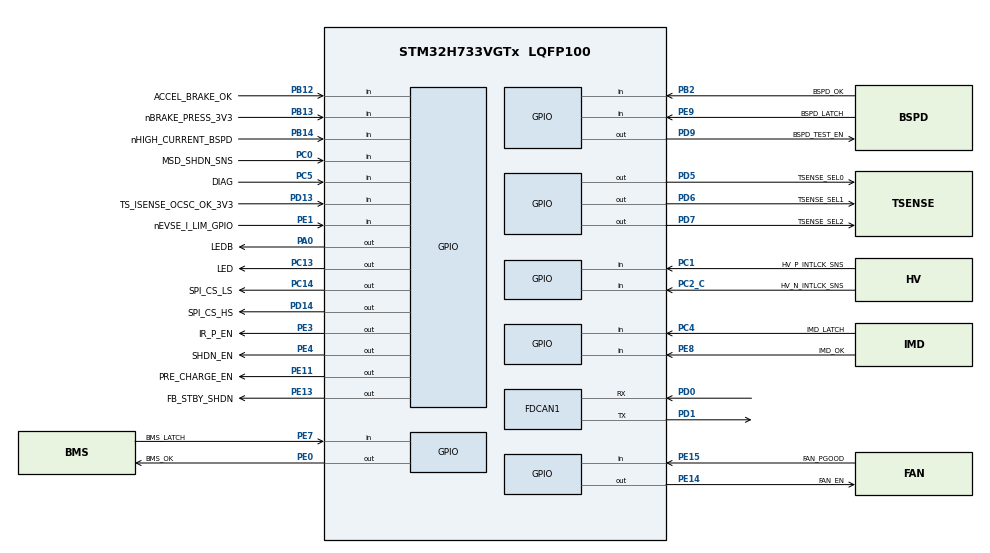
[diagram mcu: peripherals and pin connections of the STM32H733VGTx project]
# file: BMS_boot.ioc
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CORTEX_M7.default_mode_Activation=0
FDCAN1.AutoRetransmission=ENABLE
FDCAN1.CalculateBaudRateNominal=1000000
FDCAN1.CalculateTimeBitNominal=1000
FDCAN1.CalculateTimeQuantumNominal=62.5
FDCAN1.DataSyncJumpWidth=6
FDCAN1.DataTimeSeg1=17
FDCAN1.DataTimeSeg2=6
FDCAN1.ExtFiltersNbr=1
FDCAN1.FrameFormat=FDCAN_FRAME_FD_NO_BRS
FDCAN1.NominalPrescaler=6
FDCAN1.NominalSyncJumpWidth=2
FDCAN1.NominalTimeSeg1=13
FDCAN1.NominalTimeSeg2=2
FDCAN1.ProtocolException=DISABLE
FDCAN1.RxBufferSize=FDCAN_DATA_BYTES_64
FDCAN1.RxFifo0ElmtSize=FDCAN_DATA_BYTES_64
FDCAN1.RxFifo0ElmtsNbr=32
FDCAN1.RxFifo1ElmtSize=FDCAN_DATA_BYTES_64
FDCAN1.RxFifo1ElmtsNbr=0
FDCAN1.StdFiltersNbr=1
FDCAN1.TxElmtSize=FDCAN_DATA_BYTES_64
FDCAN1.TxFifoQueueElmtsNbr=32
FREERTOS.Tasks01=interfaceTask,48,512,runInterfaceTask,Default,NULL,Static,interfaceTaskBuffer,interfaceTaskControlBlock;canTxTask,40,512,runCanTxTask,Default,NULL,Static,canTxTaskBuffer,canTxTaskControlBlock;tickTask,16,512,runTickTask,Default,NULL,Static,tickTaskBuffer,tickTaskControlBlock
FREERTOS.configENABLE_FPU=1
FREERTOS.configUSE_NEWLIB_REENTRANT=1
Mcu.Family=STM32H7
Mcu.Name=STM32H733VGTx
Mcu.Package=LQFP100
Mcu.UserConstants=TIM3_PRESCALER,10;ADC_FREQUENCY,1000;TASKCANTX_STACK_SIZE,512;TIM1_AUTO_RELOAD_REG,0xFFFF;TIMx_FREQUENCY,550000000;IWDG_RESET_FREQUENCY,5;TASK1KHZ_STACK_SIZE,512;TIM1_FREQUENCY,275000000;TIM3_FREQUENCY,275000000;TASK100HZ_STACK_SIZE,512;TASK1HZ_STACK_SIZE,512;IWDG_WINDOW_DISABLE_VALUE,4095;IWDG_PRESCALER,4;TASKCANRX_STACK_SIZE,512;TIM1_PWM_MIN_FREQUENCY,1;LSI_FREQUENCY,32000;TIM1_PRESCALER,(TIM1_FREQUENCY / TIM1_AUTO_RELOAD_REG / TIM1_PWM_MIN_FREQUENCY);TIM5_FREQUENCY,275000000;TIM5_AUTO_RELOAD_REG,0xFFFF;TIM5_PWM_MIN_FREQUENCY,1;TIM5_PRESCALER,(TIM5_FREQUENCY / TIM5_AUTO_RELOAD_REG / TIM5_PWM_MIN_FREQUENCY)
NVIC.FDCAN1_IT0_IRQn=true\:5\:0\:false\:false\:true\:true\:true\:true\:true
NVIC.FDCAN1_IT1_IRQn=true\:5\:0\:false\:false\:true\:true\:true\:true\:true
NVIC.PriorityGroup=NVIC_PRIORITYGROUP_4
NVIC.TIM2_IRQn=true\:15\:0\:false\:false\:true\:false\:false\:true\:true
NVIC.TimeBase=TIM2_IRQn
NVIC.TimeBaseIP=TIM2
PA0.GPIO_Label=LEDB
PA0.PinState=GPIO_PIN_SET
PA0.Signal=GPIO_Output
PA13(JTMS/SWDIO).GPIO_Label=SWDIO
PA13(JTMS/SWDIO).Mode=Trace_Asynchronous_SW
PA13(JTMS/SWDIO).Signal=DEBUG_JTMS-SWDIO
PA14(JTCK/SWCLK).GPIO_Label=SWCLK
PA14(JTCK/SWCLK).Mode=Trace_Asynchronous_SW
PA14(JTCK/SWCLK).Signal=DEBUG_JTCK-SWCLK
PB12.GPIO_Label=ACCEL_BRAKE_OK
PB12.Signal=GPIO_Input
PB13.GPIO_Label=nBRAKE_PRESS_3V3
PB13.Signal=GPIO_Input
PB14.GPIO_Label=nHIGH_CURRENT_BSPD
PB14.Signal=GPIO_Input
PB2.GPIO_Label=BSPD_OK
PB2.Signal=GPIO_Input
PB3(JTDO/TRACESWO).GPIO_Label=SWO
PB3(JTDO/TRACESWO).Mode=Trace_Asynchronous_SW
PB3(JTDO/TRACESWO).Signal=DEBUG_JTDO-SWO
PB5.Signal=FDCAN2_RX
PB6.Signal=FDCAN2_TX
PC0.GPIO_Label=MSD_SHDN_SNS
PC0.Signal=GPIO_Input
PC1.GPIO_Label=HV_P_INTLCK_SNS
PC1.Signal=GPIO_Input
PC13.GPIO_Label=LED
PC13.Signal=GPIO_Output
PC14-OSC32_IN.GPIO_Label=SPI_CS_LS
PC14-OSC32_IN.GPIO_PuPd=GPIO_NOPULL
PC14-OSC32_IN.GPIO_Speed=GPIO_SPEED_FREQ_LOW
PC14-OSC32_IN.PinState=GPIO_PIN_SET
PC14-OSC32_IN.Signal=GPIO_Output
PC2_C.GPIO_Label=HV_N_INTLCK_SNS
PC2_C.Signal=GPIO_Input
PC4.GPIO_Label=IMD_LATCH
PC4.Signal=GPIO_Input
PC5.GPIO_Label=DIAG
PC5.Signal=GPIO_Input
PD0.Mode=FDCAN_Activate
PD0.Signal=FDCAN1_RX
PD1.Mode=FDCAN_Activate
PD1.Signal=FDCAN1_TX
PD13.GPIO_Label=TS_ISENSE_OCSC_OK_3V3
PD13.Signal=GPIO_Input
PD14.GPIO_Label=SPI_CS_HS
PD14.GPIO_PuPd=GPIO_NOPULL
PD14.GPIO_Speed=GPIO_SPEED_FREQ_LOW
PD14.PinState=GPIO_PIN_SET
PD14.Signal=GPIO_Output
PD5.GPIO_Label=TSENSE_SEL0
PD5.Signal=GPIO_Output
PD6.GPIO_Label=TSENSE_SEL1
PD6.Signal=GPIO_Output
PD7.GPIO_Label=TSENSE_SEL2
PD7.Signal=GPIO_Output
PD9.GPIO_Label=BSPD_TEST_EN
PD9.Signal=GPIO_Output
PE0.GPIO_Label=BMS_OK
PE0.Signal=GPIO_Output
PE1.GPIO_Label=nEVSE_I_LIM_GPIO
PE1.Signal=GPIO_Input
PE11.GPIO_Label=PRE_CHARGE_EN
PE11.GPIO_PuPd=GPIO_PULLDOWN
PE11.Signal=GPIO_Output
PE13.GPIO_Label=FB_STBY_SHDN
PE13.Signal=GPIO_Output
PE14.GPIO_Label=FAN_EN
PE14.GPIO_ModeDefaultOutputPP=GPIO_MODE_OUTPUT_OD
PE14.GPIO_PuPd=GPIO_NOPULL
PE14.Signal=GPIO_Output
PE15.GPIO_Label=FAN_PGOOD
PE15.Signal=GPIO_Input
PE3.GPIO_Label=IR_P_EN
PE3.Signal=GPIO_Output
PE4.GPIO_Label=SHDN_EN
PE4.Signal=GPIO_Output
PE7.GPIO_Label=BMS_LATCH
PE7.Signal=GPIO_Input
PE8.GPIO_Label=IMD_OK
PE8.Signal=GPIO_Input
PE9.GPIO_Label=BSPD_LATCH
PE9.Signal=GPIO_Input
PH0-OSC_IN.Mode=HSE-External-Oscillator
PH0-OSC_IN.Signal=RCC_OSC_IN
PH1-OSC_OUT.Mode=HSE-External-Oscillator
PH1-OSC_OUT.Signal=RCC_OSC_OUT
ProjectManager.HeapSize=0x200
ProjectManager.StackSize=0x400
ProjectManager.TargetToolchain=STM32CubeIDE
RCC.ADCFreq_Value=96000000
RCC.APB1Freq_Value=128000000
RCC.APB2Freq_Value=128000000
RCC.APB3Freq_Value=128000000
RCC.APB4Freq_Value=128000000
RCC.CortexFreq_Value=512000000
RCC.D1PPRE=RCC_APB3_DIV2
RCC.D2PPRE1=RCC_APB1_DIV2
RCC.D2PPRE2=RCC_APB2_DIV2
RCC.D3PPRE=RCC_APB4_DIV2
RCC.DIVM1=1
RCC.DIVM2=1
RCC.DIVM3=1
RCC.DIVN1=64
RCC.DIVN2=24
RCC.DIVN3=24
RCC.DIVP1=1
RCC.DIVQ1=4
RCC.DIVQ3=4
RCC.FDCANCLockSelection=RCC_FDCANCLKSOURCE_PLL2
RCC.HCLKFreq_Value=256000000
RCC.HPRE=RCC_HCLK_DIV2
RCC.HSE_VALUE=8000000
RCC.HSIDiv=RCC_PLLSAIDIVR_8
RCC.PLL2FRACN=0
RCC.PLL3FRACN=0
RCC.PLLFRACN=0
RCC.PLLSourceVirtual=RCC_PLLSOURCE_HSE
RCC.SYSCLKFreq_VALUE=512000000
RCC.SYSCLKSource=RCC_SYSCLKSOURCE_PLLCLK
RCC.Spi45ClockSelection=RCC_SPI45CLKSOURCE_PLL2
RCC.USBCLockSelection=RCC_USBCLKSOURCE_PLL3
RCC.USBFreq_Value=48000000
VP_FREERTOS_VS_CMSIS_V2.Mode=CMSIS_V2
VP_MEMORYMAP_VS_MEMORYMAP.Mode=CurAppReg
VP_SYS_VS_tim2.Mode=TIM2
board=custom

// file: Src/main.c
/* USER CODE BEGIN Header */
/**
 ******************************************************************************
 * @file           : main.c
 * @brief          : Main program body
 ******************************************************************************
 * @attention
 *
 * Copyright (c) 2024 STMicroelectronics.
 * All rights reserved.
 *
 * This software is licensed under terms that can be found in the LICENSE file
 * in the root directory of this software component.
 * If no LICENSE file comes with this software, it is provided AS-IS.
 *
 ******************************************************************************
 */
/* USER CODE END Header */
#include "main.h"
#include "cmsis_os.h"

/* USER CODE BEGIN Includes */
#include "hw/fdcan.h"
#include "hw/error.h"
#include "io/canQueue.h"

#include "bootloader.h"
/* USER CODE END Includes */

typedef StaticTask_t osStaticThreadDef_t;

FDCAN_HandleTypeDef hfdcan1;

/* Definitions for interfaceTask */
osThreadId_t         interfaceTaskHandle;
uint32_t             interfaceTaskBuffer[512];
osStaticThreadDef_t  interfaceTaskControlBlock;
const osThreadAttr_t interfaceTask_attributes = {
    .name       = "interfaceTask",
    .cb_mem     = &interfaceTaskControlBlock,
    .cb_size    = sizeof(interfaceTaskControlBlock),
    .stack_mem  = &interfaceTaskBuffer[0],
    .stack_size = sizeof(interfaceTaskBuffer),
    .priority   = (osPriority_t)osPriorityRealtime,
};
/* Definitions for canTxTask */
osThreadId_t         canTxTaskHandle;
uint32_t             canTxTaskBuffer[512];
osStaticThreadDef_t  canTxTaskControlBlock;
const osThreadAttr_t canTxTask_attributes = {
    .name       = "canTxTask",
    .cb_mem     = &canTxTaskControlBlock,
    .cb_size    = sizeof(canTxTaskControlBlock),
    .stack_mem  = &canTxTaskBuffer[0],
    .stack_size = sizeof(canTxTaskBuffer),
    .priority   = (osPriority_t)osPriorityHigh,
};
/* Definitions for tickTask */
osThreadId_t         tickTaskHandle;
uint32_t             tickTaskBuffer[512];
osStaticThreadDef_t  tickTaskControlBlock;
const osThreadAttr_t tickTask_attributes = {
    .name       = "tickTask",
    .cb_mem     = &tickTaskControlBlock,
    .cb_size    = sizeof(tickTaskControlBlock),
    .stack_mem  = &tickTaskBuffer[0],
    .stack_size = sizeof(tickTaskBuffer),
    .priority   = (osPriority_t)osPriorityBelowNormal,
};
/* USER CODE BEGIN PV */
CanHandle can = { .bus_num = 0, .hcan = &hfdcan1, .receive_callback = io_canQueue_pushRx, .ready = false };
/* USER CODE END PV */

void        SystemClock_Config(void);
static void MX_GPIO_Init(void);
static void MX_FDCAN1_Init(void);
void        runInterfaceTask(void *argument);
void        runCanTxTask(void *argument);
void        runTickTask(void *argument);

int main(void)
{
    /* USER CODE BEGIN 1 */
    bootloader_preInit();
    /* USER CODE END 1 */

    /* MCU Configuration--------------------------------------------------------*/

    /* Reset of all peripherals, Initializes the Flash interface and the Systick. */
    HAL_Init();

    /* Configure the system clock */
    SystemClock_Config();

    /* Initialize all configured peripherals */
    MX_GPIO_Init();
    MX_FDCAN1_Init();
    /* USER CODE BEGIN 2 */
    bootloader_init();
    /* USER CODE END 2 */

    /* Init scheduler */
    osKernelInitialize();

    /* Create the thread(s) */
    /* creation of interfaceTask */
    interfaceTaskHandle = osThreadNew(runInterfaceTask, NULL, &interfaceTask_attributes);

    /* creation of canTxTask */
    canTxTaskHandle = osThreadNew(runCanTxTask, NULL, &canTxTask_attributes);

    /* creation of tickTask */
    tickTaskHandle = osThreadNew(runTickTask, NULL, &tickTask_attributes);

    /* Start scheduler */
    osKernelStart();

    /* We should never get here as control is now taken by the scheduler */

    /* Infinite loop */
    while (1)
    {

    }
}

void SystemClock_Config(void)
{
    RCC_OscInitTypeDef RCC_OscInitStruct = { 0 };
    RCC_ClkInitTypeDef RCC_ClkInitStruct = { 0 };

    /** Supply configuration update enable
     */
    HAL_PWREx_ConfigSupply(PWR_LDO_SUPPLY);

    /** Configure the main internal regulator output voltage
     */
    __HAL_PWR_VOLTAGESCALING_CONFIG(PWR_REGULATOR_VOLTAGE_SCALE0);

    while (!__HAL_PWR_GET_FLAG(PWR_FLAG_VOSRDY))
    {
    }

    /** Initializes the RCC Oscillators according to the specified parameters
     * in the RCC_OscInitTypeDef structure.
     */
    RCC_OscInitStruct.OscillatorType = RCC_OSCILLATORTYPE_HSE;
    RCC_OscInitStruct.HSEState       = RCC_HSE_ON;
    RCC_OscInitStruct.PLL.PLLState   = RCC_PLL_ON;
    RCC_OscInitStruct.PLL.PLLSource  = RCC_PLLSOURCE_HSE;
    RCC_OscInitStruct.PLL.PLLM       = 1;
    RCC_OscInitStruct.PLL.PLLN       = 64;
    RCC_OscInitStruct.PLL.PLLP       = 1;
    RCC_OscInitStruct.PLL.PLLQ       = 4;
    RCC_OscInitStruct.PLL.PLLR       = 2;
    RCC_OscInitStruct.PLL.PLLRGE     = RCC_PLL1VCIRANGE_3;
    RCC_OscInitStruct.PLL.PLLVCOSEL  = RCC_PLL1VCOWIDE;
    RCC_OscInitStruct.PLL.PLLFRACN   = 0;
    if (HAL_RCC_OscConfig(&RCC_OscInitStruct) != HAL_OK)
    {
        Error_Handler();
    }

    /** Initializes the CPU, AHB and APB buses clocks
     */
    RCC_ClkInitStruct.ClockType = RCC_CLOCKTYPE_HCLK | RCC_CLOCKTYPE_SYSCLK | RCC_CLOCKTYPE_PCLK1 |
                                  RCC_CLOCKTYPE_PCLK2 | RCC_CLOCKTYPE_D3PCLK1 | RCC_CLOCKTYPE_D1PCLK1;
    RCC_ClkInitStruct.SYSCLKSource   = RCC_SYSCLKSOURCE_PLLCLK;
    RCC_ClkInitStruct.SYSCLKDivider  = RCC_SYSCLK_DIV1;
    RCC_ClkInitStruct.AHBCLKDivider  = RCC_HCLK_DIV2;
    RCC_ClkInitStruct.APB3CLKDivider = RCC_APB3_DIV2;
    RCC_ClkInitStruct.APB1CLKDivider = RCC_APB1_DIV2;
    RCC_ClkInitStruct.APB2CLKDivider = RCC_APB2_DIV2;
    RCC_ClkInitStruct.APB4CLKDivider = RCC_APB4_DIV2;

    if (HAL_RCC_ClockConfig(&RCC_ClkInitStruct, FLASH_LATENCY_3) != HAL_OK)
    {
        Error_Handler();
    }
}

static void MX_FDCAN1_Init(void)
{

    hfdcan1.Instance                  = FDCAN1;
    hfdcan1.Init.FrameFormat          = FDCAN_FRAME_FD_NO_BRS;
    hfdcan1.Init.Mode                 = FDCAN_MODE_NORMAL;
    hfdcan1.Init.AutoRetransmission   = ENABLE;
    hfdcan1.Init.TransmitPause        = DISABLE;
    hfdcan1.Init.ProtocolException    = DISABLE;
    hfdcan1.Init.NominalPrescaler     = 6;
    hfdcan1.Init.NominalSyncJumpWidth = 2;
    hfdcan1.Init.NominalTimeSeg1      = 13;
    hfdcan1.Init.NominalTimeSeg2      = 2;
    hfdcan1.Init.DataPrescaler        = 1;
    hfdcan1.Init.DataSyncJumpWidth    = 6;
    hfdcan1.Init.DataTimeSeg1         = 17;
    hfdcan1.Init.DataTimeSeg2         = 6;
    hfdcan1.Init.MessageRAMOffset     = 0;
    hfdcan1.Init.StdFiltersNbr        = 1;
    hfdcan1.Init.ExtFiltersNbr        = 1;
    hfdcan1.Init.RxFifo0ElmtsNbr      = 32;
    hfdcan1.Init.RxFifo0ElmtSize      = FDCAN_DATA_BYTES_64;
    hfdcan1.Init.RxFifo1ElmtsNbr      = 0;
    hfdcan1.Init.RxFifo1ElmtSize      = FDCAN_DATA_BYTES_64;
    hfdcan1.Init.RxBuffersNbr         = 0;
    hfdcan1.Init.RxBufferSize         = FDCAN_DATA_BYTES_64;
    hfdcan1.Init.TxEventsNbr          = 0;
    hfdcan1.Init.TxBuffersNbr         = 0;
    hfdcan1.Init.TxFifoQueueElmtsNbr  = 32;
    hfdcan1.Init.TxFifoQueueMode      = FDCAN_TX_FIFO_OPERATION;
    hfdcan1.Init.TxElmtSize           = FDCAN_DATA_BYTES_64;
    if (HAL_FDCAN_Init(&hfdcan1) != HAL_OK)
    {
        Error_Handler();
    }
}

static void MX_GPIO_Init(void)
{
    GPIO_InitTypeDef GPIO_InitStruct = { 0 };

    /* GPIO Ports Clock Enable */
    __HAL_RCC_GPIOE_CLK_ENABLE();
    __HAL_RCC_GPIOC_CLK_ENABLE();
    __HAL_RCC_GPIOH_CLK_ENABLE();
    __HAL_RCC_GPIOA_CLK_ENABLE();
    __HAL_RCC_GPIOB_CLK_ENABLE();
    __HAL_RCC_GPIOD_CLK_ENABLE();

    /*Configure GPIO pin Output Level */
    HAL_GPIO_WritePin(
        GPIOE, IR_P_EN_Pin | SHDN_EN_Pin | PRE_CHARGE_EN_Pin | FB_STBY_SHDN_Pin | FAN_EN_Pin | BMS_OK_Pin,
        GPIO_PIN_RESET);

    /*Configure GPIO pin Output Level */
    HAL_GPIO_WritePin(LED_GPIO_Port, LED_Pin, GPIO_PIN_RESET);

    /*Configure GPIO pin Output Level */
    HAL_GPIO_WritePin(SPI_CS_LS_GPIO_Port, SPI_CS_LS_Pin, GPIO_PIN_SET);

    /*Configure GPIO pin Output Level */
    HAL_GPIO_WritePin(LEDB_GPIO_Port, LEDB_Pin, GPIO_PIN_SET);

    /*Configure GPIO pin Output Level */
    HAL_GPIO_WritePin(GPIOD, BSPD_TEST_EN_Pin | TSENSE_SEL0_Pin | TSENSE_SEL1_Pin | TSENSE_SEL2_Pin, GPIO_PIN_RESET);

    /*Configure GPIO pin Output Level */
    HAL_GPIO_WritePin(SPI_CS_HS_GPIO_Port, SPI_CS_HS_Pin, GPIO_PIN_SET);

    /*Configure GPIO pins : IR_P_EN_Pin SHDN_EN_Pin FB_STBY_SHDN_Pin BMS_OK_Pin */
    GPIO_InitStruct.Pin   = IR_P_EN_Pin | SHDN_EN_Pin | FB_STBY_SHDN_Pin | BMS_OK_Pin;
    GPIO_InitStruct.Mode  = GPIO_MODE_OUTPUT_PP;
    GPIO_InitStruct.Pull  = GPIO_NOPULL;
    GPIO_InitStruct.Speed = GPIO_SPEED_FREQ_LOW;
    HAL_GPIO_Init(GPIOE, &GPIO_InitStruct);

    /*Configure GPIO pins : LED_Pin SPI_CS_LS_Pin */
    GPIO_InitStruct.Pin   = LED_Pin | SPI_CS_LS_Pin;
    GPIO_InitStruct.Mode  = GPIO_MODE_OUTPUT_PP;
    GPIO_InitStruct.Pull  = GPIO_NOPULL;
    GPIO_InitStruct.Speed = GPIO_SPEED_FREQ_LOW;
    HAL_GPIO_Init(GPIOC, &GPIO_InitStruct);

    /*Configure GPIO pins : MSD_SHDN_SNS_Pin HV_P_INTLCK_SNS_Pin HV_N_INTLCK_SNS_Pin IMD_LATCH_Pin
                             DIAG_Pin */
    GPIO_InitStruct.Pin  = MSD_SHDN_SNS_Pin | HV_P_INTLCK_SNS_Pin | HV_N_INTLCK_SNS_Pin | IMD_LATCH_Pin | DIAG_Pin;
    GPIO_InitStruct.Mode = GPIO_MODE_INPUT;
    GPIO_InitStruct.Pull = GPIO_NOPULL;
    HAL_GPIO_Init(GPIOC, &GPIO_InitStruct);

    /*Configure GPIO pin : LEDB_Pin */
    GPIO_InitStruct.Pin   = LEDB_Pin;
    GPIO_InitStruct.Mode  = GPIO_MODE_OUTPUT_PP;
    GPIO_InitStruct.Pull  = GPIO_NOPULL;
    GPIO_InitStruct.Speed = GPIO_SPEED_FREQ_LOW;
    HAL_GPIO_Init(LEDB_GPIO_Port, &GPIO_InitStruct);

    /*Configure GPIO pins : BSPD_OK_Pin ACCEL_BRAKE_OK_Pin nBRAKE_PRESS_3V3_Pin nHIGH_CURRENT_BSPD_Pin */
    GPIO_InitStruct.Pin  = BSPD_OK_Pin | ACCEL_BRAKE_OK_Pin | nBRAKE_PRESS_3V3_Pin | nHIGH_CURRENT_BSPD_Pin;
    GPIO_InitStruct.Mode = GPIO_MODE_INPUT;
    GPIO_InitStruct.Pull = GPIO_NOPULL;
    HAL_GPIO_Init(GPIOB, &GPIO_InitStruct);

    /*Configure GPIO pins : BMS_LATCH_Pin IMD_OK_Pin BSPD_LATCH_Pin FAN_PGOOD_Pin
                             nEVSE_I_LIM_GPIO_Pin */
    GPIO_InitStruct.Pin  = BMS_LATCH_Pin | IMD_OK_Pin | BSPD_LATCH_Pin | FAN_PGOOD_Pin | nEVSE_I_LIM_GPIO_Pin;
    GPIO_InitStruct.Mode = GPIO_MODE_INPUT;
    GPIO_InitStruct.Pull = GPIO_NOPULL;
    HAL_GPIO_Init(GPIOE, &GPIO_InitStruct);

    /*Configure GPIO pin : PRE_CHARGE_EN_Pin */
    GPIO_InitStruct.Pin   = PRE_CHARGE_EN_Pin;
    GPIO_InitStruct.Mode  = GPIO_MODE_OUTPUT_PP;
    GPIO_InitStruct.Pull  = GPIO_PULLDOWN;
    GPIO_InitStruct.Speed = GPIO_SPEED_FREQ_LOW;
    HAL_GPIO_Init(PRE_CHARGE_EN_GPIO_Port, &GPIO_InitStruct);

    /*Configure GPIO pin : FAN_EN_Pin */
    GPIO_InitStruct.Pin   = FAN_EN_Pin;
    GPIO_InitStruct.Mode  = GPIO_MODE_OUTPUT_OD;
    GPIO_InitStruct.Pull  = GPIO_NOPULL;
    GPIO_InitStruct.Speed = GPIO_SPEED_FREQ_LOW;
    HAL_GPIO_Init(FAN_EN_GPIO_Port, &GPIO_InitStruct);

    /*Configure GPIO pins : BSPD_TEST_EN_Pin SPI_CS_HS_Pin TSENSE_SEL0_Pin TSENSE_SEL1_Pin
                             TSENSE_SEL2_Pin */
    GPIO_InitStruct.Pin   = BSPD_TEST_EN_Pin | SPI_CS_HS_Pin | TSENSE_SEL0_Pin | TSENSE_SEL1_Pin | TSENSE_SEL2_Pin;
    GPIO_InitStruct.Mode  = GPIO_MODE_OUTPUT_PP;
    GPIO_InitStruct.Pull  = GPIO_NOPULL;
    GPIO_InitStruct.Speed = GPIO_SPEED_FREQ_LOW;
    HAL_GPIO_Init(GPIOD, &GPIO_InitStruct);

    /*Configure GPIO pin : TS_ISENSE_OCSC_OK_3V3_Pin */
    GPIO_InitStruct.Pin  = TS_ISENSE_OCSC_OK_3V3_Pin;
    GPIO_InitStruct.Mode = GPIO_MODE_INPUT;
    GPIO_InitStruct.Pull = GPIO_NOPULL;
    HAL_GPIO_Init(TS_ISENSE_OCSC_OK_3V3_GPIO_Port, &GPIO_InitStruct);

    /*Configure GPIO pins : PB5 PB6 */
    GPIO_InitStruct.Pin       = GPIO_PIN_5 | GPIO_PIN_6;
    GPIO_InitStruct.Mode      = GPIO_MODE_AF_PP;
    GPIO_InitStruct.Pull      = GPIO_NOPULL;
    GPIO_InitStruct.Speed     = GPIO_SPEED_FREQ_LOW;
    GPIO_InitStruct.Alternate = GPIO_AF9_FDCAN2;
    HAL_GPIO_Init(GPIOB, &GPIO_InitStruct);

}

void runInterfaceTask(void *argument)
{
    /* USER CODE BEGIN 5 */
    /* Infinite loop */
    bootloader_runInterfaceTask();
    /* USER CODE END 5 */
}

void runCanTxTask(void *argument)
{
    /* USER CODE BEGIN runCanTxTask */
    /* Infinite loop */
    bootloader_runCanTxTask();
    /* USER CODE END runCanTxTask */
}

void runTickTask(void *argument)
{
    /* USER CODE BEGIN runTickTask */
    /* Infinite loop */
    bootloader_runTickTask();
    /* USER CODE END runTickTask */
}

void HAL_TIM_PeriodElapsedCallback(TIM_HandleTypeDef *htim)
{
    if (htim->Instance == TIM2)
    {
        HAL_IncTick();
    }
}

void Error_Handler(void)
{
    __disable_irq();
    while (1)
    {
    }
}
